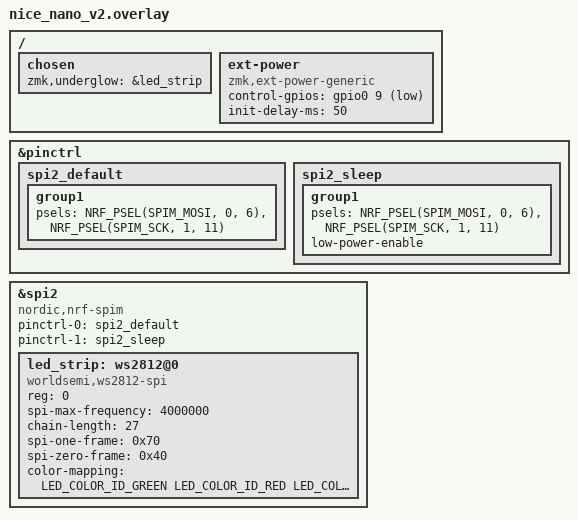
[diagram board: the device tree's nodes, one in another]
#include <dt-bindings/led/led.h>

&pinctrl {

    spi2_default: spi2_default {
        group1 {
            psels = <NRF_PSEL(SPIM_MOSI, 0, 6)>,
                    <NRF_PSEL(SPIM_SCK, 1, 11)>; /* dummy SCK on pad 14 = P1.11 (actually unconnected); previously had (1,6)=P1.06=pad 9 which is ENC_B */
        };
    };

    spi2_sleep: spi2_sleep {
        group1 {
            psels = <NRF_PSEL(SPIM_MOSI, 0, 6)>,
                    <NRF_PSEL(SPIM_SCK, 1, 11)>;
            low-power-enable;
        };
    };
};

&spi2 {
    compatible = "nordic,nrf-spim";
    status = "okay";

    pinctrl-0 = <&spi2_default>;
    pinctrl-1 = <&spi2_sleep>;
    pinctrl-names = "default", "sleep";

    led_strip: ws2812@0 {
        compatible = "worldsemi,ws2812-spi";

        /* SPI */
        reg = <0>;
        spi-max-frequency = <4000000>;

        /* WS2812 */
        chain-length = <27>; /* 6 underglow + 21 per-key, per half */
        spi-one-frame = <0x70>;
        spi-zero-frame = <0x40>;

        color-mapping = <LED_COLOR_ID_GREEN LED_COLOR_ID_RED LED_COLOR_ID_BLUE>;
    };
};

/ {
    chosen {
        zmk,underglow = &led_strip;
    };

    /* nice!nano's stock EXT_POWER node uses P0.13 (its default LED pin) and
     * collides with our /ext-power below: both normalize to the same DT
     * symbol, leaving instance 0 with undefined config. Delete the stock
     * node so only ours remains. */
    /delete-node/ EXT_POWER;

    ext-power {
        compatible = "zmk,ext-power-generic";
        control-gpios = <&gpio0 9 GPIO_ACTIVE_LOW>; /* ProMicro pad 13 = P0.09 = D10, MOSFET gate */
        init-delay-ms = <50>;
    };
};
